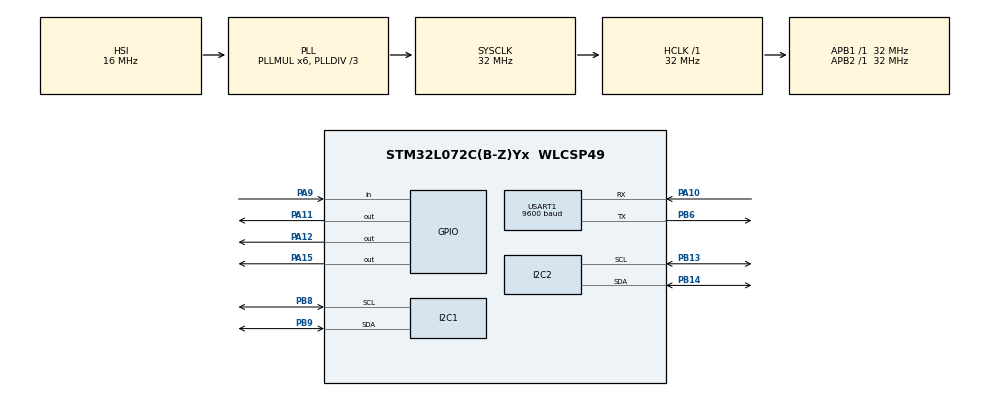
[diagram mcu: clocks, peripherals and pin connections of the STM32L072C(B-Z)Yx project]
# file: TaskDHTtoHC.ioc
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FREERTOS.Tasks01=defaultTask,24,128,StartDefaultTask,Default,NULL,Dynamic,NULL,NULL;TaskDHT,24,256,StartTask02,Default,NULL,Dynamic,NULL,NULL;TaskHC,8,256,StartTask03,Default,NULL,Dynamic,NULL,NULL
FREERTOS.configUSE_NEWLIB_REENTRANT=1
I2C1.Timing=0x00B07CB4
I2C2.Timing=0x00B07CB4
Mcu.Family=STM32L0
Mcu.Name=STM32L072C(B-Z)Yx
Mcu.Package=WLCSP49
NVIC.TIM2_IRQn=true\:3\:0\:false\:false\:true\:false\:false\:true\:true
NVIC.TimeBase=TIM2_IRQn
NVIC.TimeBaseIP=TIM2
PA10.Mode=Asynchronous
PA10.Signal=USART1_RX
PA11.Signal=GPIO_Output
PA12.Signal=GPIO_Output
PA15.Signal=GPIO_Output
PA9.Signal=GPIO_Input
PB13.Mode=I2C
PB13.Signal=I2C2_SCL
PB14.Mode=I2C
PB14.Signal=I2C2_SDA
PB6.Mode=Asynchronous
PB6.Signal=USART1_TX
PB8.Mode=I2C
PB8.Signal=I2C1_SCL
PB9.Mode=I2C
PB9.Signal=I2C1_SDA
ProjectManager.HeapSize=0x200
ProjectManager.StackSize=0x400
ProjectManager.TargetToolchain=STM32CubeIDE
RCC.AHBFreq_Value=32000000
RCC.APB1Freq_Value=32000000
RCC.APB1TimFreq_Value=32000000
RCC.APB2Freq_Value=32000000
RCC.APB2TimFreq_Value=32000000
RCC.HCLKFreq_Value=32000000
RCC.HSE_VALUE=8000000
RCC.HSI16_VALUE=16000000
RCC.HSI48_VALUE=48000000
RCC.HSI_VALUE=16000000
RCC.LSE_VALUE=32768
RCC.MSI_VALUE=2097000
RCC.PLLDIV=RCC_PLLDIV_3
RCC.PLLMUL=RCC_PLLMUL_6
RCC.SYSCLKFreq_VALUE=32000000
RCC.SYSCLKSource=RCC_SYSCLKSOURCE_PLLCLK
RCC.VCOOutputFreq_Value=96000000
USART1.BaudRate=9600
USART1.OverSampling=UART_OVERSAMPLING_8
USART1.VirtualMode-Asynchronous=VM_ASYNC
VP_FREERTOS_VS_CMSIS_V2.Mode=CMSIS_V2
VP_SYS_VS_tim2.Mode=TIM2
board=B-L072Z-LRWAN1

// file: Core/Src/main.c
/**
  **********
  * @file           : main.c
  * @brief          : Main program body
  **********
  * @attention
  *
  * Copyright (c) 2025 STMicroelectronics.
  * All rights reserved.
  *
  * This software is licensed under terms that can be found in the LICENSE file
  * in the root directory of this software component.
  * If no LICENSE file comes with this software, it is provided AS-IS.
  *
  **********
  */
/* USER CODE END Header */
#include "main.h"
#include "cmsis_os.h"

/* USER CODE BEGIN Includes */
#include <stdio.h>
#include <string.h>
/* Private includes ----------------------------------------------------------*/
/* USER CODE BEGIN Includes */
/* USER CODE END Includes */

#define BMP280_I2C_ADDRESS 0x76
#define BMP280_REG_ID 0xD0
#define BMP280_REG_CTRL_MEAS 0xF4
#define BMP280_REG_CONFIG 0xF5
#define BMP280_REG_PRESS_MSB 0xF7
#define BMP280_REG_TEMP_MSB 0xFA

I2C_HandleTypeDef hi2c1;
I2C_HandleTypeDef hi2c2;
osSemaphoreId_t sensorSemaphoreHandle = NULL; // Semaphore handle for synchronization
osSemaphoreId_t taskSyncSemaphoreHandle = NULL;
osMutexId_t tempPressMutexHandle;

UART_HandleTypeDef huart1;

///* Definitions for defaultTask */
//osThreadId_t defaultTaskHandle;
//const osThreadAttr_t defaultTask_attributes = {
//  .name = "defaultTask",
//  .stack_size = 128 * 4,
//  .priority = (osPriority_t) osPriorityNormal,
//};
/* Definitions for TaskDHT */
osThreadId_t TaskDHTHandle;
const osThreadAttr_t TaskDHT_attributes = {
  .name = "TaskDHT",
  .stack_size = 256 * 4,
  .priority = (osPriority_t) osPriorityNormal,
};
/* Definitions for TaskHC */
osThreadId_t TaskHCHandle;
const osThreadAttr_t TaskHC_attributes = {
  .name = "TaskHC",
  .stack_size = 256 * 4,
  .priority = (osPriority_t) osPriorityLow,
};
osThreadId_t CommTask;
const osThreadAttr_t CommTask_attributes = {
  .name = "TaskComm",
  .stack_size = 256 * 4,
  .priority = (osPriority_t) osPriorityLow,
};
const osMutexAttr_t tempPressMutex_attributes = {
    .name = "tempPressMutex"
};

void SystemClock_Config(void);
static void MX_GPIO_Init(void);
static void MX_USART1_UART_Init(void);
static void MX_I2C1_Init(void);
static void MX_I2C2_Init(void);
//void StartDefaultTask(void *argument);
void StartTask02(void *argument);
void StartTask03(void *argument);
void StartTask04(void *argument);
//tempPressMutex = osMutexNew(&tempPressMutex_attributes);

uint8_t bmp280_data[6];
char mq2_buffer[64];

float temperature = 0.0;
float pressure = 0.0;

char uart_buffer[64];
void BMP280_Init(void);
void BMP280_ReadTempPress(float *temperature, float *pressure);

void BMP280_Init(void)
{
    uint8_t device_id, config[2];

    // Verificare Device ID
    uint8_t reg = BMP280_REG_ID;
    HAL_I2C_Master_Transmit(&hi2c1, BMP280_I2C_ADDRESS << 1, &reg, 1, HAL_MAX_DELAY);
    HAL_I2C_Master_Receive(&hi2c1, BMP280_I2C_ADDRESS << 1, &device_id, 1, HAL_MAX_DELAY);

    if (device_id != 0x58) {
        Error_Handler();  // Device ID incorrect
    }

    // Configurarea registrului de control măsurare
    config[0] = BMP280_REG_CTRL_MEAS;
    config[1] = 0x27; // 0x27: mod normal, oversampling x1 pentru temperatură și presiune
    HAL_I2C_Master_Transmit(&hi2c1, BMP280_I2C_ADDRESS << 1, config, 2, HAL_MAX_DELAY);

    // Configurarea registrului de configurare (standby 0.5ms, fără filtru)
    config[0] = BMP280_REG_CONFIG;
    config[1] = 0xA0; // 0xA0: standby time 0.5ms, fără filtru
    HAL_I2C_Master_Transmit(&hi2c1, BMP280_I2C_ADDRESS << 1, config, 2, HAL_MAX_DELAY);
}

void BMP280_ReadTempPress(float *temperature, float *pressure)
{
    uint8_t reg[1] = {BMP280_REG_PRESS_MSB};  // 0xF7 - MSB Presiune
    HAL_I2C_Master_Transmit(&hi2c1, BMP280_I2C_ADDRESS << 1, reg, 1, HAL_MAX_DELAY);

    // Citirea celor 6 octeți pentru presiune și temperatură
    uint8_t data[6] = {0};
    HAL_I2C_Master_Receive(&hi2c1, BMP280_I2C_ADDRESS << 1, data, 6, HAL_MAX_DELAY);

    // Extrageți datele de temperatură și presiune
    int32_t adc_T = (int32_t)((data[3] << 12) | (data[4] << 4) | (data[5] >> 4));
    int32_t adc_P = (int32_t)((data[0] << 12) | (data[1] << 4) | (data[2] >> 4));

    // Convertire date temperatură
    *temperature = adc_T / 20000.0;  // Simplificare pentru demonstrație (precizie scăzută)

    // Convertire date presiune
    *pressure = adc_P / 395.0;     // Simplificare pentru demonstrație (precizie scăzută)
}

int main(void)
{

  /* MCU Configuration--------------------------------------------------------*/

  /* Reset of all peripherals, Initializes the Flash interface and the Systick. */
  HAL_Init();

  /* Configure the system clock */
  SystemClock_Config();

  /* Initialize all configured peripherals */
  MX_GPIO_Init();
  MX_USART1_UART_Init();
  MX_I2C1_Init();
  MX_I2C2_Init();

  /* Init scheduler */
  osKernelInitialize();

  /* Create the thread(s) */
  taskSyncSemaphoreHandle = osSemaphoreNew(1, 0, NULL); // Semafor binar, inițial „neacordat”

  sensorSemaphoreHandle = osSemaphoreNew(1, 1, NULL); // Binary semaphore, initialized to 1 (available)
  /* creation of defaultTask */
//  defaultTaskHandle = osThreadNew(StartDefaultTask, NULL, &defaultTask_attributes);
  tempPressMutexHandle = osMutexNew(&tempPressMutex_attributes);

  /* creation of TaskDHT */
  TaskDHTHandle = osThreadNew(StartTask02, NULL, &TaskDHT_attributes);
  CommTask = osThreadNew(StartTask04, NULL, &CommTask_attributes);

  /* creation of TaskHC */
  TaskHCHandle = osThreadNew(StartTask03, NULL, &TaskHC_attributes);

  /* Start scheduler */
  osKernelStart();

  /* We should never get here as control is now taken by the scheduler */

  /* Infinite loop */
  while (1)
  {

  }
}

void SystemClock_Config(void)
{
  RCC_OscInitTypeDef RCC_OscInitStruct = {0};
  RCC_ClkInitTypeDef RCC_ClkInitStruct = {0};
  RCC_PeriphCLKInitTypeDef PeriphClkInit = {0};

  /** Configure the main internal regulator output voltage
  */
  __HAL_PWR_VOLTAGESCALING_CONFIG(PWR_REGULATOR_VOLTAGE_SCALE1);

  /** Initializes the RCC Oscillators according to the specified parameters
  * in the RCC_OscInitTypeDef structure.
  */
  RCC_OscInitStruct.OscillatorType = RCC_OSCILLATORTYPE_HSI;
  RCC_OscInitStruct.HSIState = RCC_HSI_ON;
  RCC_OscInitStruct.HSICalibrationValue = RCC_HSICALIBRATION_DEFAULT;
  RCC_OscInitStruct.PLL.PLLState = RCC_PLL_ON;
  RCC_OscInitStruct.PLL.PLLSource = RCC_PLLSOURCE_HSI;
  RCC_OscInitStruct.PLL.PLLMUL = RCC_PLLMUL_6;
  RCC_OscInitStruct.PLL.PLLDIV = RCC_PLLDIV_3;
  if (HAL_RCC_OscConfig(&RCC_OscInitStruct) != HAL_OK)
  {
    Error_Handler();
  }

  /** Initializes the CPU, AHB and APB buses clocks
  */
  RCC_ClkInitStruct.ClockType = RCC_CLOCKTYPE_HCLK|RCC_CLOCKTYPE_SYSCLK
                              |RCC_CLOCKTYPE_PCLK1|RCC_CLOCKTYPE_PCLK2;
  RCC_ClkInitStruct.SYSCLKSource = RCC_SYSCLKSOURCE_PLLCLK;
  RCC_ClkInitStruct.AHBCLKDivider = RCC_SYSCLK_DIV1;
  RCC_ClkInitStruct.APB1CLKDivider = RCC_HCLK_DIV1;
  RCC_ClkInitStruct.APB2CLKDivider = RCC_HCLK_DIV1;

  if (HAL_RCC_ClockConfig(&RCC_ClkInitStruct, FLASH_LATENCY_1) != HAL_OK)
  {
    Error_Handler();
  }
  PeriphClkInit.PeriphClockSelection = RCC_PERIPHCLK_USART1|RCC_PERIPHCLK_I2C1;
  PeriphClkInit.Usart1ClockSelection = RCC_USART1CLKSOURCE_PCLK2;
  PeriphClkInit.I2c1ClockSelection = RCC_I2C1CLKSOURCE_PCLK1;
  if (HAL_RCCEx_PeriphCLKConfig(&PeriphClkInit) != HAL_OK)
  {
    Error_Handler();
  }
}

static void MX_I2C1_Init(void)
{

  hi2c1.Instance = I2C1;
  hi2c1.Init.Timing = 0x00B07CB4;
  hi2c1.Init.OwnAddress1 = 0;
  hi2c1.Init.AddressingMode = I2C_ADDRESSINGMODE_7BIT;
  hi2c1.Init.DualAddressMode = I2C_DUALADDRESS_DISABLE;
  hi2c1.Init.OwnAddress2 = 0;
  hi2c1.Init.OwnAddress2Masks = I2C_OA2_NOMASK;
  hi2c1.Init.GeneralCallMode = I2C_GENERALCALL_DISABLE;
  hi2c1.Init.NoStretchMode = I2C_NOSTRETCH_DISABLE;
  if (HAL_I2C_Init(&hi2c1) != HAL_OK)
  {
    Error_Handler();
  }

  /** Configure Analogue filter
  */
  if (HAL_I2CEx_ConfigAnalogFilter(&hi2c1, I2C_ANALOGFILTER_ENABLE) != HAL_OK)
  {
    Error_Handler();
  }

  /** Configure Digital filter
  */
  if (HAL_I2CEx_ConfigDigitalFilter(&hi2c1, 0) != HAL_OK)
  {
    Error_Handler();
  }

}

static void MX_I2C2_Init(void)
{

  hi2c2.Instance = I2C2;
  hi2c2.Init.Timing = 0x00B07CB4;
  hi2c2.Init.OwnAddress1 = 0;
  hi2c2.Init.AddressingMode = I2C_ADDRESSINGMODE_7BIT;
  hi2c2.Init.DualAddressMode = I2C_DUALADDRESS_DISABLE;
  hi2c2.Init.OwnAddress2 = 0;
  hi2c2.Init.OwnAddress2Masks = I2C_OA2_NOMASK;
  hi2c2.Init.GeneralCallMode = I2C_GENERALCALL_DISABLE;
  hi2c2.Init.NoStretchMode = I2C_NOSTRETCH_DISABLE;
  if (HAL_I2C_Init(&hi2c2) != HAL_OK)
  {
    Error_Handler();
  }

  /** Configure Analogue filter
  */
  if (HAL_I2CEx_ConfigAnalogFilter(&hi2c2, I2C_ANALOGFILTER_ENABLE) != HAL_OK)
  {
    Error_Handler();
  }

  /** Configure Digital filter
  */
  if (HAL_I2CEx_ConfigDigitalFilter(&hi2c2, 0) != HAL_OK)
  {
    Error_Handler();
  }

}

static void MX_USART1_UART_Init(void)
{

  huart1.Instance = USART1;
  huart1.Init.BaudRate = 9600;
  huart1.Init.WordLength = UART_WORDLENGTH_8B;
  huart1.Init.StopBits = UART_STOPBITS_1;
  huart1.Init.Parity = UART_PARITY_NONE;
  huart1.Init.Mode = UART_MODE_TX_RX;
  huart1.Init.HwFlowCtl = UART_HWCONTROL_NONE;
  huart1.Init.OverSampling = UART_OVERSAMPLING_8;
  huart1.Init.OneBitSampling = UART_ONE_BIT_SAMPLE_DISABLE;
  huart1.AdvancedInit.AdvFeatureInit = UART_ADVFEATURE_NO_INIT;
  if (HAL_UART_Init(&huart1) != HAL_OK)
  {
    Error_Handler();
  }

}

static void MX_GPIO_Init(void)
{
  GPIO_InitTypeDef GPIO_InitStruct = {0};

  /* GPIO Ports Clock Enable */
  __HAL_RCC_GPIOA_CLK_ENABLE();
  __HAL_RCC_GPIOB_CLK_ENABLE();

  /*Configure GPIO pin Output Level */
  HAL_GPIO_WritePin(GPIOA, GPIO_PIN_15|GPIO_PIN_12, GPIO_PIN_RESET);

  /*Configure GPIO pins : PA15 PA12 */
  GPIO_InitStruct.Pin = GPIO_PIN_15|GPIO_PIN_12;
  GPIO_InitStruct.Mode = GPIO_MODE_OUTPUT_PP;
  GPIO_InitStruct.Pull = GPIO_NOPULL;
  GPIO_InitStruct.Speed = GPIO_SPEED_FREQ_LOW;
  HAL_GPIO_Init(GPIOA, &GPIO_InitStruct);

  /*Configure GPIO pins : PA11 PA9 */
  GPIO_InitStruct.Pin = GPIO_PIN_11;
  GPIO_InitStruct.Mode = GPIO_MODE_INPUT;
  GPIO_InitStruct.Pull = GPIO_NOPULL;
  HAL_GPIO_Init(GPIOA, &GPIO_InitStruct);

}

//void StartDefaultTask(void *argument)
//{
//  /* USER CODE BEGIN 5 */
//  /* Infinite loop */
//  for(;;)
//  {
//    osDelay(1);
//  }
//  /* USER CODE END 5 */
//}

void StartTask02(void *argument)
{
    for (;;)
    {
        uint8_t gas_detected = HAL_GPIO_ReadPin(GPIOA, GPIO_PIN_11);

        if (gas_detected)
        {
            snprintf(mq2_buffer, sizeof(mq2_buffer), "MQ-2: Gas detected\r\n");
        }
        else
        {
            snprintf(mq2_buffer, sizeof(mq2_buffer), "MQ-2: No gas detected\r\n");
        }

        // Transmite datele prin HC-05
        HAL_UART_Transmit(&huart1, (uint8_t *)mq2_buffer, strlen(mq2_buffer), HAL_MAX_DELAY);

        osSemaphoreRelease(taskSyncSemaphoreHandle);  // Eliberează semaforul pentru Task03

        osDelay(1000);  // Task02 interval
    }
}
void StartTask03(void *argument)
{
    BMP280_Init();

    for (;;)
    {
        HAL_GPIO_WritePin(GPIOA, GPIO_PIN_12, GPIO_PIN_SET);

        // Lock mutex to protect access to temperature and pressure
        tempPressMutexHandle = osMutexNew(&tempPressMutex_attributes);
        osMutexAcquire(tempPressMutexHandle, osWaitForever);

        // Read data from BMP280
        BMP280_ReadTempPress(&temperature, &pressure);

        // Unlock mutex after reading data
        osMutexRelease(tempPressMutexHandle);

        HAL_GPIO_WritePin(GPIOA, GPIO_PIN_12, GPIO_PIN_RESET);

        // Release semaphore for Task04 to transmit data
        osSemaphoreRelease(taskSyncSemaphoreHandle);

        osDelay(500);  // Short delay for stability
    }
}
void StartTask04(void *argument)
{
	float citire_temp =0;
	float citire_pres =0;
    for (;;)
    {
        // Wait for the semaphore from Task03 to transmit data
        osSemaphoreAcquire(taskSyncSemaphoreHandle, osWaitForever);

        // Lock mutex to safely access temperature and pressure
        osMutexAcquire(tempPressMutexHandle, osWaitForever);
        citire_temp = temperature;
        citire_pres = pressure;
        // Unlock mutex after accessing data
        osMutexRelease(tempPressMutexHandle);
        // Transmit data from BMP280
        snprintf(uart_buffer, sizeof(uart_buffer), "Temp: %.2f C, Press: %.2f hPa\r\n", citire_temp, citire_pres);
        HAL_UART_Transmit(&huart1, (uint8_t *)uart_buffer, strlen(uart_buffer), HAL_MAX_DELAY);

        osDelay(2000);  // Delay between transmissions for Task04
    }
}
void HAL_TIM_PeriodElapsedCallback(TIM_HandleTypeDef *htim)
{
  /* USER CODE BEGIN Callback 0 */
//
  /* USER CODE END Callback 0 */
  if (htim->Instance == TIM2) {
    HAL_IncTick();
  }
  /* USER CODE BEGIN Callback 1 */
//
  /* USER CODE END Callback 1 */
}

void Error_Handler(void)
{
  __disable_irq();
  while (1)
  {
  }
}
